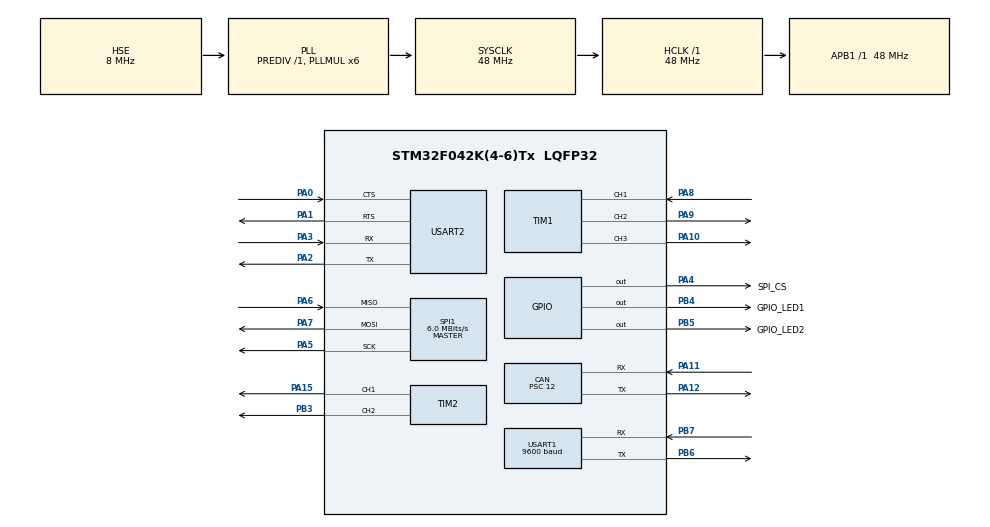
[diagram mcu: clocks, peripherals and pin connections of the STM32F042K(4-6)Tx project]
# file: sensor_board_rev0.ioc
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CAN.BS1=CAN_BS1_2TQ
CAN.BS2=CAN_BS2_2TQ
CAN.CalculateBaudRate=800000
CAN.CalculateTimeBit=1250
CAN.CalculateTimeQuantum=250.0
CAN.Prescaler=12
Dma.Request0=USART1_RX
Dma.USART1_RX.0.Direction=DMA_PERIPH_TO_MEMORY
Dma.USART1_RX.0.Instance=DMA1_Channel3
Dma.USART1_RX.0.MemDataAlignment=DMA_MDATAALIGN_BYTE
Dma.USART1_RX.0.MemInc=DMA_MINC_ENABLE
Dma.USART1_RX.0.Mode=DMA_CIRCULAR
Dma.USART1_RX.0.PeriphDataAlignment=DMA_PDATAALIGN_BYTE
Dma.USART1_RX.0.PeriphInc=DMA_PINC_DISABLE
Dma.USART1_RX.0.Priority=DMA_PRIORITY_LOW
Mcu.Family=STM32F0
Mcu.Name=STM32F042K(4-6)Tx
Mcu.Package=LQFP32
NVIC.DMA1_Channel2_3_IRQn=true\:0\:0\:false\:false\:true\:false\:true\:true
NVIC.TIM14_IRQn=true\:3\:0\:false\:false\:true\:false\:true\:true
NVIC.TIM16_IRQn=true\:0\:0\:false\:false\:true\:true\:true\:true
NVIC.TIM17_IRQn=true\:0\:0\:false\:false\:true\:true\:true\:true
NVIC.TimeBase=TIM14_IRQn
NVIC.TimeBaseIP=TIM14
NVIC.USART1_IRQn=true\:0\:0\:false\:false\:true\:true\:true\:true
PA0.Mode=CTS_RTS
PA0.Signal=USART2_CTS
PA1.Mode=CTS_RTS
PA1.Signal=USART2_RTS
PA10.Signal=S_TIM1_CH3
PA11.Mode=CAN_Activate
PA11.Signal=CAN_RX
PA12.Mode=CAN_Activate
PA12.Signal=CAN_TX
PA13.Mode=Serial_Wire
PA13.Signal=SYS_SWDIO
PA14.Mode=Serial_Wire
PA14.Signal=SYS_SWCLK
PA15.Signal=S_TIM2_CH1_ETR
PA2.Mode=Asynchronous
PA2.Signal=USART2_TX
PA3.Mode=Asynchronous
PA3.Signal=USART2_RX
PA4.GPIO_Label=SPI_CS
PA4.Signal=GPIO_Output
PA5.GPIO_Speed=GPIO_SPEED_FREQ_MEDIUM
PA5.Mode=Full_Duplex_Master
PA5.Signal=SPI1_SCK
PA6.GPIO_PuPd=GPIO_PULLDOWN
PA6.GPIO_Speed=GPIO_SPEED_FREQ_MEDIUM
PA6.Mode=Full_Duplex_Master
PA6.Signal=SPI1_MISO
PA7.GPIO_Speed=GPIO_SPEED_FREQ_MEDIUM
PA7.Mode=Full_Duplex_Master
PA7.Signal=SPI1_MOSI
PA8.Signal=S_TIM1_CH1
PA9.Signal=S_TIM1_CH2
PB3.Signal=S_TIM2_CH2
PB4.GPIO_Label=GPIO_LED1
PB4.Signal=GPIO_Output
PB5.GPIO_Label=GPIO_LED2
PB5.Signal=GPIO_Output
PB6.GPIO_PuPd=GPIO_PULLUP
PB6.GPIO_Speed=GPIO_SPEED_FREQ_MEDIUM
PB6.Mode=Asynchronous
PB6.Signal=USART1_TX
PB7.GPIO_PuPd=GPIO_PULLUP
PB7.GPIO_Speed=GPIO_SPEED_FREQ_MEDIUM
PB7.Mode=Asynchronous
PB7.Signal=USART1_RX
PF0-OSC_IN.Mode=HSE-External-Oscillator
PF0-OSC_IN.Signal=RCC_OSC_IN
PF1-OSC_OUT.Mode=HSE-External-Oscillator
PF1-OSC_OUT.Signal=RCC_OSC_OUT
ProjectManager.HeapSize=0x200
ProjectManager.StackSize=0x400
ProjectManager.TargetToolchain=STM32CubeIDE
RCC.AHBFreq_Value=48000000
RCC.APB1Freq_Value=48000000
RCC.APB1TimFreq_Value=48000000
RCC.HCLKFreq_Value=48000000
RCC.PLLMUL=RCC_PLL_MUL6
RCC.PLLSourceVirtual=RCC_PLLSOURCE_HSE
RCC.SYSCLKFreq_VALUE=48000000
RCC.SYSCLKSource=RCC_SYSCLKSOURCE_PLLCLK
SH.S_TIM1_CH1.0=TIM1_CH1,TriggerSource_TI1ED
SH.S_TIM1_CH2.0=TIM1_CH2,PWM Generation2 CH2
SH.S_TIM1_CH3.0=TIM1_CH3,PWM Generation3 CH3
SH.S_TIM2_CH1_ETR.0=TIM2_CH1,PWM Generation1 CH1
SH.S_TIM2_CH2.0=TIM2_CH2,PWM Generation2 CH2
SPI1.BaudRatePrescaler=SPI_BAUDRATEPRESCALER_8
SPI1.CLKPhase=SPI_PHASE_2EDGE
SPI1.CLKPolarity=SPI_POLARITY_HIGH
SPI1.CalculateBaudRate=6.0 MBits/s
SPI1.DataSize=SPI_DATASIZE_8BIT
SPI1.Direction=SPI_DIRECTION_2LINES
SPI1.Mode=SPI_MODE_MASTER
SPI1.VirtualType=VM_MASTER
TIM1.Channel-Input_Capture1_from_TRC=TIM_CHANNEL_1
TIM1.Channel-PWM\ Generation2\ CH2=TIM_CHANNEL_2
TIM1.Channel-PWM\ Generation3\ CH3=TIM_CHANNEL_3
TIM16.Period=59999
TIM16.Prescaler=7
TIM17.Period=59999
TIM2.Channel-PWM\ Generation1\ CH1=TIM_CHANNEL_1
TIM2.Channel-PWM\ Generation2\ CH2=TIM_CHANNEL_2
USART1.BaudRate=9600
USART1.VirtualMode-Asynchronous=VM_ASYNC
USART2.VirtualMode-Asynchronous=VM_ASYNC
VP_SYS_VS_tim14.Mode=TIM14
VP_TIM16_VS_ClockSourceINT.Mode=Enable_Timer
VP_TIM17_VS_ClockSourceINT.Mode=Enable_Timer
VP_TIM1_VS_CH1.Mode=Input_Capture1_from_TRC
board=custom

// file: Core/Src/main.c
/* USER CODE BEGIN Header */
/**
  ******************************************************************************
  * @file           : main.c
  * @brief          : Main program body
  ******************************************************************************
  * @attention
  *
  * Copyright (c) 2024 STMicroelectronics.
  * All rights reserved.
  *
  * This software is licensed under terms that can be found in the LICENSE file
  * in the root directory of this software component.
  * If no LICENSE file comes with this software, it is provided AS-IS.
  *
  ******************************************************************************
  */
/* USER CODE END Header */
#include "main.h"
#include "can.h"
#include "dma.h"
#include "spi.h"
#include "tim.h"
#include "usart.h"
#include "gpio.h"

/* USER CODE BEGIN Includes */
#include "sensor_board.h"
// #include "imu.h"
// #include "can_interface.h"
#include "blinky.h"
/* USER CODE END Includes */

void SystemClock_Config(void);

int main(void)
{

  /* MCU Configuration--------------------------------------------------------*/

  /* Reset of all peripherals, Initializes the Flash interface and the Systick. */
  HAL_Init();

  /* Configure the system clock */
  SystemClock_Config();

  /* Initialize all configured peripherals */
  MX_GPIO_Init();
  MX_DMA_Init();
  MX_CAN_Init();
  MX_SPI1_Init();
  MX_USART1_UART_Init();
  MX_USART2_UART_Init();
  MX_TIM1_Init();
  MX_TIM16_Init();
  MX_TIM17_Init();
  MX_TIM2_Init();
  /* USER CODE BEGIN 2 */

  run_sensor_board();

  // PANIC IF WE REACH HERE
  NVIC_SystemReset();
  /* USER CODE END 2 */

  /* Infinite loop */
  while (1)
  {

  }
}

void SystemClock_Config(void)
{
  RCC_OscInitTypeDef RCC_OscInitStruct = {0};
  RCC_ClkInitTypeDef RCC_ClkInitStruct = {0};
  RCC_PeriphCLKInitTypeDef PeriphClkInit = {0};

  /** Initializes the RCC Oscillators according to the specified parameters
  * in the RCC_OscInitTypeDef structure.
  */
  RCC_OscInitStruct.OscillatorType = RCC_OSCILLATORTYPE_HSE;
  RCC_OscInitStruct.HSEState = RCC_HSE_ON;
  RCC_OscInitStruct.PLL.PLLState = RCC_PLL_ON;
  RCC_OscInitStruct.PLL.PLLSource = RCC_PLLSOURCE_HSE;
  RCC_OscInitStruct.PLL.PLLMUL = RCC_PLL_MUL6;
  RCC_OscInitStruct.PLL.PREDIV = RCC_PREDIV_DIV1;
  if (HAL_RCC_OscConfig(&RCC_OscInitStruct) != HAL_OK)
  {
    Error_Handler();
  }

  /** Initializes the CPU, AHB and APB buses clocks
  */
  RCC_ClkInitStruct.ClockType = RCC_CLOCKTYPE_HCLK|RCC_CLOCKTYPE_SYSCLK
                              |RCC_CLOCKTYPE_PCLK1;
  RCC_ClkInitStruct.SYSCLKSource = RCC_SYSCLKSOURCE_PLLCLK;
  RCC_ClkInitStruct.AHBCLKDivider = RCC_SYSCLK_DIV1;
  RCC_ClkInitStruct.APB1CLKDivider = RCC_HCLK_DIV1;

  if (HAL_RCC_ClockConfig(&RCC_ClkInitStruct, FLASH_LATENCY_1) != HAL_OK)
  {
    Error_Handler();
  }
  PeriphClkInit.PeriphClockSelection = RCC_PERIPHCLK_USART1;
  PeriphClkInit.Usart1ClockSelection = RCC_USART1CLKSOURCE_PCLK1;
  if (HAL_RCCEx_PeriphCLKConfig(&PeriphClkInit) != HAL_OK)
  {
    Error_Handler();
  }
}

void HAL_TIM_PeriodElapsedCallback(TIM_HandleTypeDef *htim)
{
  if (htim->Instance == TIM14) {
    HAL_IncTick();
  }
  /* USER CODE BEGIN Callback 1 */
  else if (htim->Instance == TASK_100HZ_TIM_INSTANCE) {
    task_100hz();
  } else if (htim->Instance == TASK_800HZ_TIM_INSTANCE) {
    task_800hz();
  }
  /* USER CODE END Callback 1 */
}

void Error_Handler(void)
{
  __disable_irq();
  while (1)
  {
  }
}
